AUTOSAR XML (schema 00049)
standard types defined: boolean, float32, sint16, uint16, uint8, boolean_CompuMethod, boolean_DataConstr, float32_DataConstr, sint16_DataConstr, uint16_DataConstr, uint8_DataConstr
package /ComponentTypes
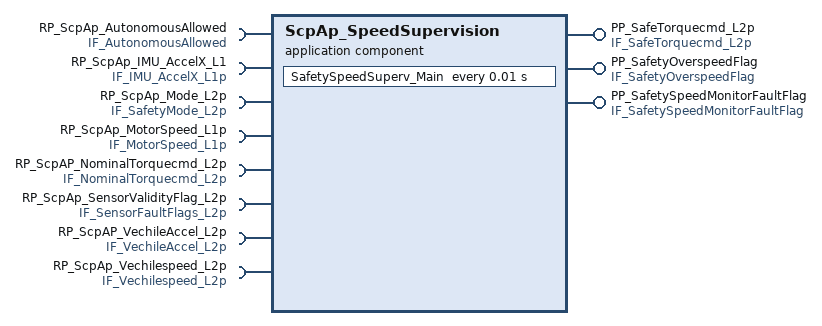
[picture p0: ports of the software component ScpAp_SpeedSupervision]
  application sw component type ScpAp_SpeedSupervision
    provide port PP_SafeTorquecmd_L2p: nonqueued-sender-com-spec{data-element=IF_SafeTorquecmd_L2p, init-value=0}, provided-interface=IF_SafeTorquecmd_L2p
    provide port PP_SafetyOverspeedFlag: nonqueued-sender-com-spec=data-element=IF_SafetyOverspeedFlag, provided-interface=IF_SafetyOverspeedFlag
    provide port PP_SafetySpeedMonitorFaultFlag: nonqueued-sender-com-spec=data-element=IF_SafetySpeedMonitorFaultFlag, provided-interface=IF_SafetySpeedMonitorFaultFlag
    8 x require port:
      RP_ScpAp_AutonomousAllowed: nonqueued-receiver-com-spec{data-element=IF_AutonomousAllowed, filter=data-filter-type=ALWAYS}, required-interface=IF_AutonomousAllowed
      RP_ScpAp_IMU_AccelX_L1: nonqueued-receiver-com-spec{data-element=IF_IMU_AccelX_L1p, filter=data-filter-type=ALWAYS}, required-interface=IF_IMU_AccelX_L1p
      RP_ScpAp_Mode_L2p: nonqueued-receiver-com-spec{data-element=IF_SafetyMode_L2p, filter=data-filter-type=ALWAYS}, required-interface=IF_SafetyMode_L2p
      RP_ScpAp_MotorSpeed_L1p: nonqueued-receiver-com-spec{data-element=IF_MotorSpeed_L1p, filter=data-filter-type=ALWAYS}, required-interface=IF_MotorSpeed_L1p
      RP_ScpAP_NominalTorquecmd_L2p: nonqueued-receiver-com-spec{data-element=IF_NominalTorquecmd_L2p, filter=data-filter-type=ALWAYS}, required-interface=IF_NominalTorquecmd_L2p
      RP_ScpAp_SensorValidityFlag_L2p: nonqueued-receiver-com-spec{data-element=IF_SensorFaultFlags_L2p, filter=data-filter-type=ALWAYS, init-value=fields=[MotorRPM_Fault:0, Accel_Fault:0, WSS_Fault:0, VechSpeedEst_Fault:0]}, required-interface=IF_SensorFaultFlags_L2p
      RP_ScpAP_VechileAccel_L2p: nonqueued-receiver-com-spec{data-element=IF_VechileAccel_L2p, filter=data-filter-type=ALWAYS, init-value=0}, required-interface=IF_VechileAccel_L2p
      RP_ScpAp_Vechilespeed_L2p: nonqueued-receiver-com-spec{data-element=IF_Vechilespeed_L2p, filter=data-filter-type=ALWAYS, init-value=0}, required-interface=IF_Vechilespeed_L2p
    behavior ScpAp_SpeedSupervision_InternalBehavior: handle-termination-and-restart=NO-SUPPORT
      timing event TMT_SaeftySpeedSuperv_Main: start-on-event=SafetySpeedSuperv_Main, period=0.01
      runnable SafetySpeedSuperv_Main
        data-receive-point-by-arguments:
          8 x access:
            REC_RP_ScpAp_AutonomousAllowed_IF_AutonomousAllowed: accessed-variable=RP_ScpAp_AutonomousAllowed.IF_AutonomousAllowed
            REC_RP_ScpAp_IMU_AccelX_L1_IF_IMU_AccelX_L1p: accessed-variable=RP_ScpAp_IMU_AccelX_L1.IF_IMU_AccelX_L1p
            REC_RP_ScpAp_Mode_L2p_IF_SafetyMode_L2p: accessed-variable=RP_ScpAp_Mode_L2p.IF_SafetyMode_L2p
            REC_RP_ScpAp_MotorSpeed_L1p_IF_MotorSpeed_L1p: accessed-variable=RP_ScpAp_MotorSpeed_L1p.IF_MotorSpeed_L1p
            REC_RP_ScpAP_NominalTorquecmd_L2p_IF_NominalTorquecmd_L2p: accessed-variable=RP_ScpAP_NominalTorquecmd_L2p.IF_NominalTorquecmd_L2p
            REC_RP_ScpAp_SensorValidityFlag_L2p_IF_SensorFaultFlags_L2p: accessed-variable=RP_ScpAp_SensorValidityFlag_L2p.IF_SensorFaultFlags_L2p
            REC_RP_ScpAP_VechileAccel_L2p_IF_VechileAccel_L2p: accessed-variable=RP_ScpAP_VechileAccel_L2p.IF_VechileAccel_L2p
            REC_RP_ScpAp_Vechilespeed_L2p_IF_Vechilespeed_L2p: accessed-variable=RP_ScpAp_Vechilespeed_L2p.IF_Vechilespeed_L2p
        data-send-points:
          access SEND_PP_SafeTorquecmd_L2p_IF_SafeTorquecmd_L2p: accessed-variable=PP_SafeTorquecmd_L2p.IF_SafeTorquecmd_L2p
          access SEND_PP_SafetyOverspeedFlag_IF_SafetyOverspeedFlag: accessed-variable=PP_SafetyOverspeedFlag.IF_SafetyOverspeedFlag
          access SEND_PP_SafetySpeedMonitorFaultFlag_IF_SafetySpeedMonitorFaultFlag: accessed-variable=PP_SafetySpeedMonitorFaultFlag.IF_SafetySpeedMonitorFaultFlag
  swc implementation ScpAp_SpeedSupervision_Implementation: behavior=ScpAp_SpeedSupervision_InternalBehavior
    code-descriptors:
      code Default: artifact-descriptors=autosar-engineering-object={short-label=Default, category=SWSRC}
package /DataTypes
  impl type IF_SensorFaultFlgs_L2p_IDT: category=STRUCTURE, sw-calibration-access=READ-ONLY, type-emitter=RTE
    4 x element, all with category=VALUE, base-type=boolean, sw-calibration-access=READ-ONLY:
      MotorRPM_Fault
      Accel_Fault
      WSS_Fault
      VechSpeedEst_Fault
  impl type SafetyMode_L2p_IDT: category=VALUE, base-type=BaseTypes/uint8, sw-calibration-access=READ-ONLY, compu {0=MANUAL (CompuScale), 1=AUTONOMOUS (CompuScale), 3=TELEOPS (CompuScale)}, type-emitter=RTE
package /PortInterfaces
  11 x sender receiver interface:
    IF_AutonomousAllowed: invalidation-policy{data-element=IF_AutonomousAllowed, handle-invalid=DONT-INVALIDATE}
      data IF_AutonomousAllowed: type=boolean
    IF_IMU_AccelX_L1p: invalidation-policy{data-element=IF_IMU_AccelX_L1p, handle-invalid=DONT-INVALIDATE}
      data IF_IMU_AccelX_L1p: type=float32
    IF_MotorSpeed_L1p: invalidation-policy{data-element=IF_MotorSpeed_L1p, handle-invalid=DONT-INVALIDATE}
      data IF_MotorSpeed_L1p: type=uint8
    IF_NominalTorquecmd_L2p: invalidation-policy{data-element=IF_NominalTorquecmd_L2p, handle-invalid=DONT-INVALIDATE}
      data IF_NominalTorquecmd_L2p: type=sint16
    IF_SafeTorquecmd_L2p: invalidation-policy{data-element=IF_SafeTorquecmd_L2p, handle-invalid=DONT-INVALIDATE}
      data IF_SafeTorquecmd_L2p: type=sint16
    IF_SafetyMode_L2p: invalidation-policy{data-element=IF_SafetyMode_L2p, handle-invalid=DONT-INVALIDATE}
      data IF_SafetyMode_L2p: type=SafetyMode_L2p_IDT
    IF_SafetyOverspeedFlag: invalidation-policy{data-element=IF_SafetyOverspeedFlag, handle-invalid=DONT-INVALIDATE}
      data IF_SafetyOverspeedFlag: type=boolean
    IF_SafetySpeedMonitorFaultFlag: invalidation-policy{data-element=IF_SafetySpeedMonitorFaultFlag, handle-invalid=DONT-INVALIDATE}
      data IF_SafetySpeedMonitorFaultFlag: type=boolean
    IF_SensorFaultFlags_L2p: invalidation-policy{data-element=IF_SensorFaultFlags_L2p, handle-invalid=DONT-INVALIDATE}
      data IF_SensorFaultFlags_L2p: type=IF_SensorFaultFlgs_L2p_IDT
    IF_VechileAccel_L2p: invalidation-policy{data-element=IF_VechileAccel_L2p, handle-invalid=DONT-INVALIDATE}
      data IF_VechileAccel_L2p: type=sint16
    IF_Vechilespeed_L2p: invalidation-policy{data-element=IF_Vechilespeed_L2p, handle-invalid=DONT-INVALIDATE}
      data IF_Vechilespeed_L2p: type=uint16
